# earlgrey register map
Vendor: lowRISC; File version: snapshot-20191101-1-539-gaf065293
CPU: other 0, little endian, no MPU, no FPU, 0 interrupt priority bits
Registers are 32-bit, read-write, reset 0x0 unless marked. A register's access mark holds for its fields unless they carry their own. Offsets are from the block's base; [hi:lo] are bit positions; lines under a group give offsets from that group; {n}, {i} and the like mark numbered series.

## pinmux
Base 0x40070000
0x00 REGEN reset 0x1 write-0-clears — Register write enable for all control registers.
  [0] wen write-0-clears — When true, all configuration registers can be modified. When false, they become read-only. Defaults true, write zero to clear.
0x04 PERIPH_INSEL group — Mux select for peripheral inputs.
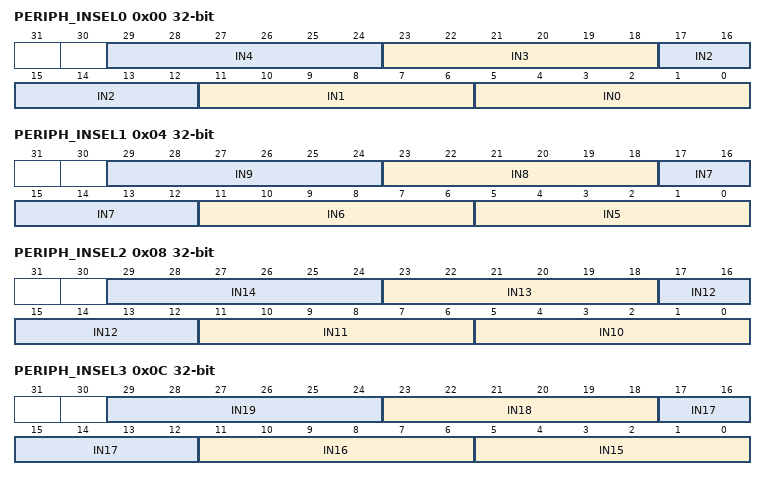
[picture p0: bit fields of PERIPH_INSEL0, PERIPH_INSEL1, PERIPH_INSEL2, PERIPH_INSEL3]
  0x00 PERIPH_INSEL0 — Mux select for peripheral inputs.
    [6n+5:6n] IN{n} (n=1..4) — for IN{n}
    [5:0] IN0 — 0: tie constantly to zero, 1: tie constantly to 1. >=2: MIO pads (i.e., add 2 to the native MIO pad index). for IN0
  0x04 PERIPH_INSEL1 — Mux select for peripheral inputs.
    [6n-25:6n-30] IN{n} (n=6..9) — for IN{n}
    [5:0] IN5 — 0: tie constantly to zero, 1: tie constantly to 1. >=2: MIO pads (i.e., add 2 to the native MIO pad index). for IN5
  0x08 PERIPH_INSEL2 — Mux select for peripheral inputs.
    [6n-55:6n-60] IN{n} (n=11..14) — for IN{n}
    [5:0] IN10 — 0: tie constantly to zero, 1: tie constantly to 1. >=2: MIO pads (i.e., add 2 to the native MIO pad index). for IN10
  0x0C PERIPH_INSEL3 — Mux select for peripheral inputs.
    [6n-85:6n-90] IN{n} (n=16..19) — for IN{n}
    [5:0] IN15 — 0: tie constantly to zero, 1: tie constantly to 1. >=2: MIO pads (i.e., add 2 to the native MIO pad index). for IN15
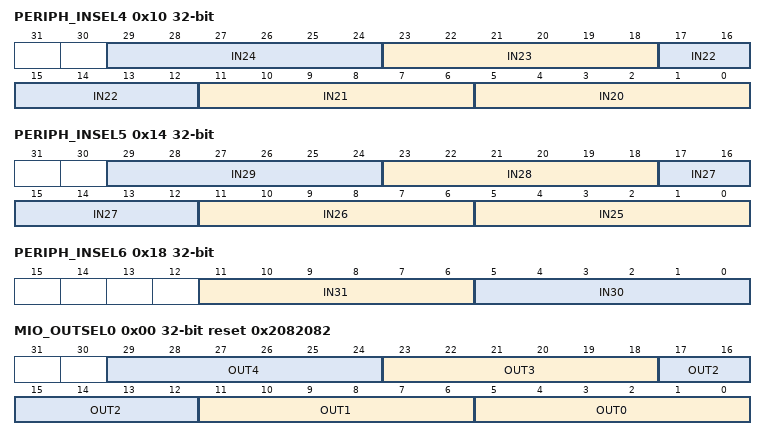
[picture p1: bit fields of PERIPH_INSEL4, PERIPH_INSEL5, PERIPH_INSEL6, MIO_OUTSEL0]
  0x10 PERIPH_INSEL4 — Mux select for peripheral inputs.
    [6n-115:6n-120] IN{n} (n=21..24) — for IN{n}
    [5:0] IN20 — 0: tie constantly to zero, 1: tie constantly to 1. >=2: MIO pads (i.e., add 2 to the native MIO pad index). for IN20
  0x14 PERIPH_INSEL5 — Mux select for peripheral inputs.
    [6n-145:6n-150] IN{n} (n=26..29) — for IN{n}
    [5:0] IN25 — 0: tie constantly to zero, 1: tie constantly to 1. >=2: MIO pads (i.e., add 2 to the native MIO pad index). for IN25
  0x18 PERIPH_INSEL6 — Mux select for peripheral inputs.
    [11:6] IN31 — for IN31
    [5:0] IN30 — 0: tie constantly to zero, 1: tie constantly to 1. >=2: MIO pads (i.e., add 2 to the native MIO pad index). for IN30
0x20 MIO_OUTSEL group — Mux select for MIO outputs.
  0x00 MIO_OUTSEL0 reset 0x2082082 — Mux select for MIO outputs.
    [6n+5:6n] OUT{n} (n=1..4) — for OUT{n}
    [5:0] OUT0 — 0: tie constantly to zero, 1: tie constantly to 1. 2: high-Z >=3: peripheral outputs (i.e., add 3 to the native peripheral pad index). for OUT0
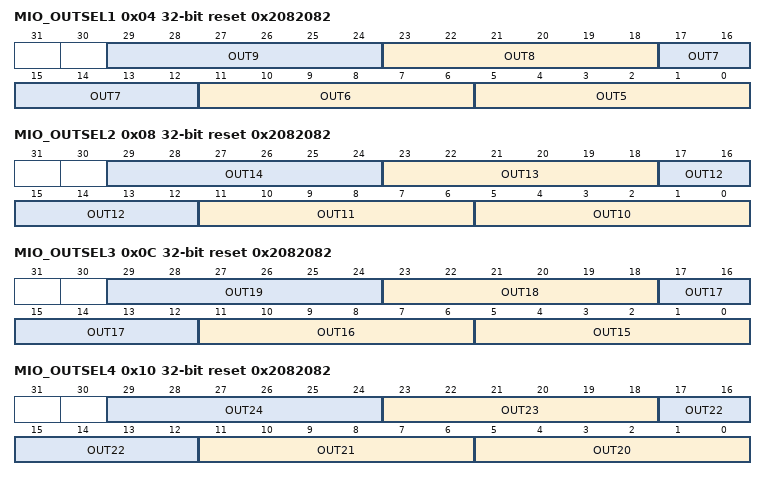
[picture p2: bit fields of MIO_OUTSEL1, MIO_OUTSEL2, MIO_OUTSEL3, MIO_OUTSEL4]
  0x04 MIO_OUTSEL1 reset 0x2082082 — Mux select for MIO outputs.
    [6n-25:6n-30] OUT{n} (n=6..9) — for OUT{n}
    [5:0] OUT5 — 0: tie constantly to zero, 1: tie constantly to 1. 2: high-Z >=3: peripheral outputs (i.e., add 3 to the native peripheral pad index). for OUT5
  0x08 MIO_OUTSEL2 reset 0x2082082 — Mux select for MIO outputs.
    [6n-55:6n-60] OUT{n} (n=11..14) — for OUT{n}
    [5:0] OUT10 — 0: tie constantly to zero, 1: tie constantly to 1. 2: high-Z >=3: peripheral outputs (i.e., add 3 to the native peripheral pad index). for OUT10
  0x0C MIO_OUTSEL3 reset 0x2082082 — Mux select for MIO outputs.
    [6n-85:6n-90] OUT{n} (n=16..19) — for OUT{n}
    [5:0] OUT15 — 0: tie constantly to zero, 1: tie constantly to 1. 2: high-Z >=3: peripheral outputs (i.e., add 3 to the native peripheral pad index). for OUT15
  0x10 MIO_OUTSEL4 reset 0x2082082 — Mux select for MIO outputs.
    [6n-115:6n-120] OUT{n} (n=21..24) — for OUT{n}
    [5:0] OUT20 — 0: tie constantly to zero, 1: tie constantly to 1. 2: high-Z >=3: peripheral outputs (i.e., add 3 to the native peripheral pad index). for OUT20
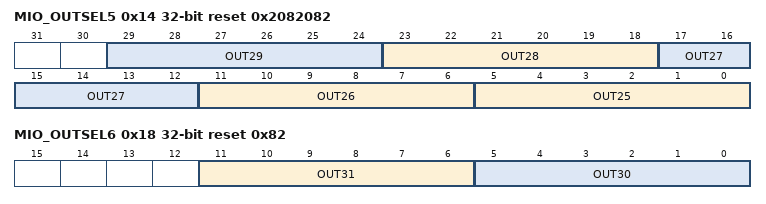
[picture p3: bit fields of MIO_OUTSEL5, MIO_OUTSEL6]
  0x14 MIO_OUTSEL5 reset 0x2082082 — Mux select for MIO outputs.
    [6n-145:6n-150] OUT{n} (n=26..29) — for OUT{n}
    [5:0] OUT25 — 0: tie constantly to zero, 1: tie constantly to 1. 2: high-Z >=3: peripheral outputs (i.e., add 3 to the native peripheral pad index). for OUT25
  0x18 MIO_OUTSEL6 reset 0x82 — Mux select for MIO outputs.
    [11:6] OUT31 — for OUT31
    [5:0] OUT30 — 0: tie constantly to zero, 1: tie constantly to 1. 2: high-Z >=3: peripheral outputs (i.e., add 3 to the native peripheral pad index). for OUT30

## rv_plic
Base 0x40090000
0x00 IP group — Interrupt Pending
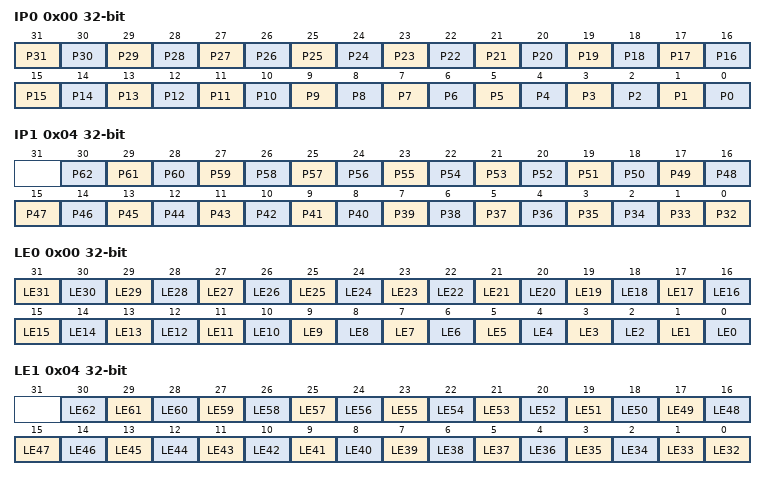
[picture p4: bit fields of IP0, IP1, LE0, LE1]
  0x00 IP0 ro — Interrupt Pending
    [n] P{n} (n=1..31) — for RV_PLIC{n}
    [0] P0 — Interrupt Pending of Source for RV_PLIC0
  0x04 IP1 ro — Interrupt Pending
    [n-32] P{n} (n=33..62) — for RV_PLIC{n}
    [0] P32 — Interrupt Pending of Source for RV_PLIC32
0x08 LE group — Interrupt Source mode. 0: Level, 1: Edge-triggered
  0x00 LE0 — Interrupt Source mode. 0: Level, 1: Edge-triggered
    [n] LE{n} (n=1..31) — for RV_PLIC{n}
    [0] LE0 — L0E1 for RV_PLIC0
  0x04 LE1 — Interrupt Source mode. 0: Level, 1: Edge-triggered
    [n-32] LE{n} (n=33..62) — for RV_PLIC{n}
    [0] LE32 — L0E1 for RV_PLIC32
{0x10+4i} PRIO{i} 2-bit (i=0..62) — Interrupt Source {i} Priority
0x200 IE0 group — Interrupt Enable for Target 0
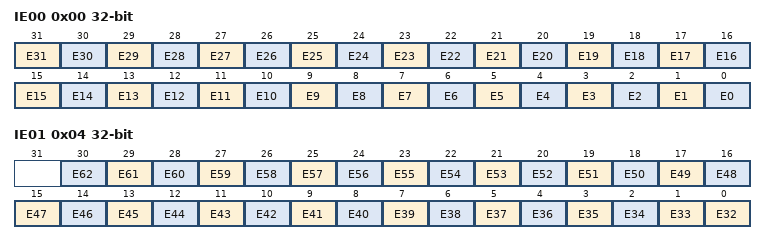
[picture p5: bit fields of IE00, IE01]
  0x00 IE00 — Interrupt Enable for Target 0
    [n] E{n} (n=1..31) — for RV_PLIC{n}
    [0] E0 — Interrupt Enable of Source for RV_PLIC0
  0x04 IE01 — Interrupt Enable for Target 0
    [n-32] E{n} (n=33..62) — for RV_PLIC{n}
    [0] E32 — Interrupt Enable of Source for RV_PLIC32
0x208 THRESHOLD0 2-bit — Threshold of priority for Target 0
0x20C CC0 6-bit — Claim interrupt by read, complete interrupt by write for Target 0. Value read/written is interrupt ID. Reading a value of 0 means no pending interrupts.
0x210 MSIP0 1-bit — msip for Hart 0. Write 1 to here asserts software interrupt for Hart msip_o[0], write 0 to clear.

## nmi_gen
Base 0x40140000
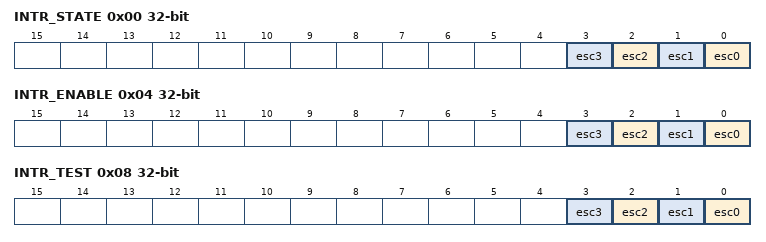
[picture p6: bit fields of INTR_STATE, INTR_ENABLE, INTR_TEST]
0x00 INTR_STATE — Interrupt State Register
  [n] esc{n} write-1-clears (n=0..3) — Escalation interrupt {n}
0x04 INTR_ENABLE — Interrupt Enable Register
  [n] esc{n} (n=0..3) — Enable interrupt when !!INTR_STATE.esc{n} is set
0x08 INTR_TEST wo — Interrupt Test Register
  [n] esc{n} (n=0..3) — Write 1 to force !!INTR_STATE.esc{n} to 1
